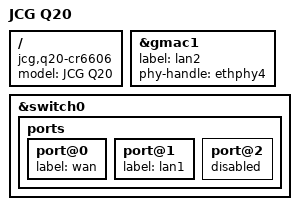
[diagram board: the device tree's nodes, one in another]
// SPDX-License-Identifier: GPL-2.0-or-later OR MIT
#include "mt7621_xiaomi_mi-router-cr660x.dtsi"

/ {
	compatible = "jcg,q20-cr6606", "mediatek,mt7621-soc";
	model = "JCG Q20";
};

&gmac1 {
	status = "okay";
	label = "lan2";
	phy-handle = <&ethphy4>;
};

&switch0 {
	ports {
		port@0 {
			status = "okay";
			label = "wan";
		};
		port@1 {
			status = "okay";
			label = "lan1";
		};
		port@2 {
			status = "disabled";
		};
	};
};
